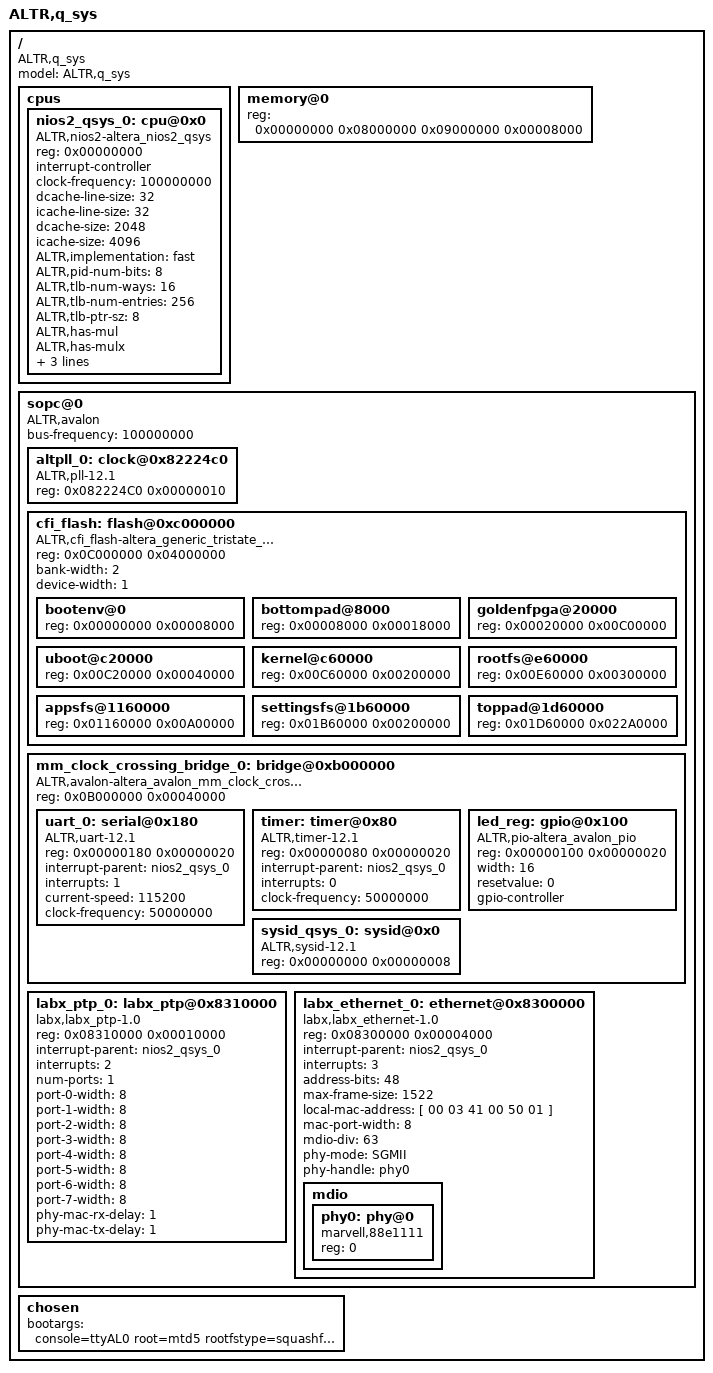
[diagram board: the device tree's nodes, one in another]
/*
 * This devicetree is generated by sopc2dts on Tue Apr 09 21:41:56 EDT 2013
 * Sopc2dts is written by Walter Goossens <waltergoossens@home.nl>
 * in cooperation with the nios2 community <Nios2-dev@sopc.et.ntust.edu.tw>
 */
/dts-v1/;

/ {
	model = "ALTR,q_sys";
	compatible = "ALTR,q_sys";
	#address-cells = < 1 >;
	#size-cells = < 1 >;

	cpus {
		#address-cells = < 1 >;
		#size-cells = < 0 >;

		nios2_qsys_0: cpu@0x0 {
			device_type = "cpu";
			compatible = "ALTR,nios2-altera_nios2_qsys";
			reg = < 0x00000000 >;
			interrupt-controller;
			#interrupt-cells = < 1 >;
			clock-frequency = < 100000000 >;	/* embeddedsw.CMacro.CPU_FREQ type NUMBER */
			dcache-line-size = < 32 >;	/* embeddedsw.CMacro.DCACHE_LINE_SIZE type NUMBER */
			icache-line-size = < 32 >;	/* embeddedsw.CMacro.ICACHE_LINE_SIZE type NUMBER */
			dcache-size = < 2048 >;	/* embeddedsw.CMacro.DCACHE_SIZE type NUMBER */
			icache-size = < 4096 >;	/* embeddedsw.CMacro.ICACHE_SIZE type NUMBER */
			ALTR,implementation = "fast";	/* embeddedsw.CMacro.CPU_IMPLEMENTATION type STRING*/
			ALTR,pid-num-bits = < 8 >;	/* embeddedsw.CMacro.PROCESS_ID_NUM_BITS type NUMBER */
			ALTR,tlb-num-ways = < 16 >;	/* embeddedsw.CMacro.TLB_NUM_WAYS type NUMBER */
			ALTR,tlb-num-entries = < 256 >;	/* embeddedsw.CMacro.TLB_NUM_ENTRIES type NUMBER */
			ALTR,tlb-ptr-sz = < 8 >;	/* embeddedsw.CMacro.TLB_PTR_SZ type NUMBER */
			ALTR,has-mul;	/* embeddedsw.CMacro.HARDWARE_MULTIPLY_PRESENT type NUMBER*/
			ALTR,has-mulx;	/* embeddedsw.CMacro.HARDWARE_MULX_PRESENT type NUMBER*/
			ALTR,reset-addr = < 0xccc20000 >;	/* embeddedsw.CMacro.RESET_ADDR type NUMBER */
			ALTR,fast-tlb-miss-addr = < 0xc9000000 >;	/* embeddedsw.CMacro.FAST_TLB_MISS_EXCEPTION_ADDR type NUMBER */
			ALTR,exception-addr = < 0xc0000020 >;	/* embeddedsw.CMacro.EXCEPTION_ADDR type NUMBER */
		}; //end cpu@0x0 (nios2_qsys_0)
	}; //end cpus

	memory@0 {
		device_type = "memory";
		reg = < 0x00000000 0x08000000
			0x09000000 0x00008000 >;
	}; //end memory@0

	sopc@0 {
		device_type = "soc";
		ranges;
		#address-cells = < 1 >;
		#size-cells = < 1 >;
		compatible = "ALTR,avalon", "simple-bus";
		bus-frequency = < 100000000 >;

		altpll_0: clock@0x82224c0 {
			compatible = "ALTR,pll-12.1", "ALTR,pll-1.0";
			reg = < 0x082224C0 0x00000010 >;
		}; //end clock@0x82224c0 (altpll_0)

		cfi_flash: flash@0xc000000 {
			compatible = "ALTR,cfi_flash-altera_generic_tristate_controller", "cfi-flash";
			reg = < 0x0C000000 0x04000000 >;
			bank-width = < 2 >;
			device-width = < 1 >;
			#address-cells = < 1 >;
			#size-cells = < 1 >;

			bootenv@0 {
				reg = < 0x00000000 0x00008000 >;
			}; //end bootenv@0

			bottompad@8000 {
				reg = < 0x00008000 0x00018000 >;
			}; //end bottompad@8000

			goldenfpga@20000 {
				reg = < 0x00020000 0x00C00000 >;
			}; //end goldenfpga@20000

			uboot@c20000 {
				reg = < 0x00C20000 0x00040000 >;
			}; //end uboot@c20000

			kernel@c60000 {
				reg = < 0x00C60000 0x00200000 >;
			}; //end kernel@c60000

			rootfs@e60000 {
				reg = < 0x00E60000 0x00300000 >;
			}; //end rootfs@e60000

			appsfs@1160000 {
				reg = < 0x01160000 0x00A00000 >;
			}; //end appsfs@1160000

			settingsfs@1b60000 {
				reg = < 0x01B60000 0x00200000 >;
			}; //end settingsfs@1b60000

			toppad@1d60000 {
				reg = < 0x01D60000 0x022A0000 >;
			}; //end toppad@1d60000
		}; //end flash@0xc000000 (cfi_flash)

		mm_clock_crossing_bridge_0: bridge@0xb000000 {
			compatible = "ALTR,avalon-altera_avalon_mm_clock_crossing_bridge", "simple-bus";
			reg = < 0x0B000000 0x00040000 >;
			#address-cells = < 1 >;
			#size-cells = < 1 >;
			ranges = < 0x00000180 0x0B000180 0x00000020
				0x00000080 0x0B000080 0x00000020
				0x00000100 0x0B000100 0x00000020
				0x00000000 0x0B000000 0x00000008 >;

			uart_0: serial@0x180 {
				compatible = "ALTR,uart-12.1", "ALTR,uart-1.0";
				reg = < 0x00000180 0x00000020 >;
				interrupt-parent = < &nios2_qsys_0 >;
				interrupts = < 1 >;
				current-speed = < 115200 >;	/* embeddedsw.CMacro.BAUD type NUMBER */
				clock-frequency = < 50000000 >;	/* embeddedsw.CMacro.FREQ type NUMBER */
			}; //end serial@0x180 (uart_0)

			timer: timer@0x80 {
				compatible = "ALTR,timer-12.1", "ALTR,timer-1.0";
				reg = < 0x00000080 0x00000020 >;
				interrupt-parent = < &nios2_qsys_0 >;
				interrupts = < 0 >;
				clock-frequency = < 50000000 >;
			}; //end timer@0x80 (timer)

			led_reg: gpio@0x100 {
				compatible = "ALTR,pio-altera_avalon_pio";
				reg = < 0x00000100 0x00000020 >;
				width = < 16 >;	/* width type NUMBER */
				resetvalue = < 0 >;	/* resetValue type NUMBER */
				#gpio-cells = < 2 >;
				gpio-controller;
			}; //end gpio@0x100 (led_reg)

			sysid_qsys_0: sysid@0x0 {
				compatible = "ALTR,sysid-12.1", "ALTR,sysid-1.0";
				reg = < 0x00000000 0x00000008 >;
			}; //end sysid@0x0 (sysid_qsys_0)
		}; //end bridge@0xb000000 (mm_clock_crossing_bridge_0)

		labx_ptp_0: labx_ptp@0x8310000 {
			compatible = "labx,labx_ptp-1.0";
			reg = < 0x08310000 0x00010000 >;
			interrupt-parent = < &nios2_qsys_0 >;
			interrupts = < 2 >;
			num-ports = < 1 >;	/* NUM_PORTS type NUMBER */
			port-0-width = < 8 >;	/* PORT_0_WIDTH type NUMBER */
			port-1-width = < 8 >;	/* PORT_1_WIDTH type NUMBER */
			port-2-width = < 8 >;	/* PORT_2_WIDTH type NUMBER */
			port-3-width = < 8 >;	/* PORT_3_WIDTH type NUMBER */
			port-4-width = < 8 >;	/* PORT_4_WIDTH type NUMBER */
			port-5-width = < 8 >;	/* PORT_5_WIDTH type NUMBER */
			port-6-width = < 8 >;	/* PORT_6_WIDTH type NUMBER */
			port-7-width = < 8 >;	/* PORT_7_WIDTH type NUMBER */
			phy-mac-rx-delay = < 1 >;	/* PHY_MAC_RX_DELAY type NUMBER */
			phy-mac-tx-delay = < 1 >;	/* PHY_MAC_TX_DELAY type NUMBER */
		}; //end labx_ptp@0x8310000 (labx_ptp_0)

		labx_ethernet_0: ethernet@0x8300000 {
			compatible = "labx,labx_ethernet-1.0";
			reg = < 0x08300000 0x00004000 >;
			interrupt-parent = < &nios2_qsys_0 >;
			interrupts = < 3 >;
			address-bits = < 48 >;
			max-frame-size = < 1522 >;
			local-mac-address = [ 00 03 41 00 50 01 ];
			mac-port-width = < 8 >;
			mdio-div = < 63 >;
			phy-mode = "SGMII";

      // HAND-ENTERED!  Need to generate this...
			phy-handle = <&phy0>;
			mdio {
				#address-cells = <1>;
				#size-cells = <0>;
				phy0: phy@0{
					compatible = "marvell,88e1111";
					device_type = "ethernet-phy";
					reg = <0>;
				};
			};
		}; //end ethernet@0x8300000 (labx_ethernet_0)
	}; //end sopc@0

	chosen {
		bootargs = "console=ttyAL0 root=mtd5 rootfstype=squashfs init=/bin/init";
	}; //end chosen
}; //end /
